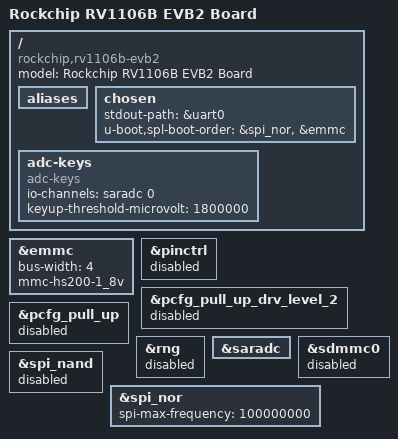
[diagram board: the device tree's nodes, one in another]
/*
 * SPDX-License-Identifier:     GPL-2.0+
 *
 * (C) Copyright 2024 Rockchip Electronics Co., Ltd
 */

/dts-v1/;
#include "rv1103b.dtsi"
#include "rv1103b-u-boot.dtsi"
#include <dt-bindings/input/input.h>

/ {
	model = "Rockchip RV1106B EVB2 Board";
	compatible = "rockchip,rv1106b-evb2", "rockchip,rv1106b";

	aliases {
		/delete-property/ ethernet0;
	};

	chosen {
		stdout-path = &uart0;
		u-boot,spl-boot-order = &spi_nor, &emmc;
	};

	adc-keys {
		compatible = "adc-keys";
		io-channels = <&saradc 0>;
		io-channel-names = "buttons";
		keyup-threshold-microvolt = <1800000>;
		u-boot,dm-spl;
		status = "okay";

	};
};

&emmc {
	bus-width = <4>;
	mmc-hs200-1_8v;
};

/delete-node/ &gmac;

&pinctrl {
	/delete-property/ u-boot,dm-spl;
	status = "disabled";
};

&pcfg_pull_up_drv_level_2 {
	/delete-property/ u-boot,dm-spl;
	status = "disabled";
};

&pcfg_pull_up {
	/delete-property/ u-boot,dm-spl;
	status = "disabled";
};

&rng {
	/delete-property/ u-boot,dm-spl;
	status = "disabled";
};

&saradc {
	u-boot,dm-spl;
	status = "okay";
};

&sdmmc0 {
	/delete-property/ u-boot,dm-spl;
	status = "disabled";
};

&spi_nand {
	/delete-property/ u-boot,dm-spl;
	status = "disabled";
};

&spi_nor {
	spi-max-frequency = <100000000>;
};
